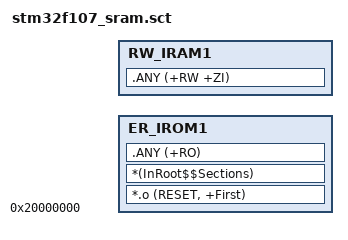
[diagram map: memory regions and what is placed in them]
;*******************************************************************
;* STM32F107 linker scatter file (running code from internal SRAM) *
;*******************************************************************

LR_IROM1 0x20000000 0x10000
{
   ER_IROM1 0x20000000
   {
      *.o (RESET, +First)
      *(InRoot$$Sections)
      .ANY (+RO)
   }
   
   RW_IRAM1 +0
   { 
      .ANY (+RW +ZI)
   }
   
   ScatterAssert((ImageLength(ER_IROM1) + ImageLength(RW_IRAM1)) < 0x10000)
}
